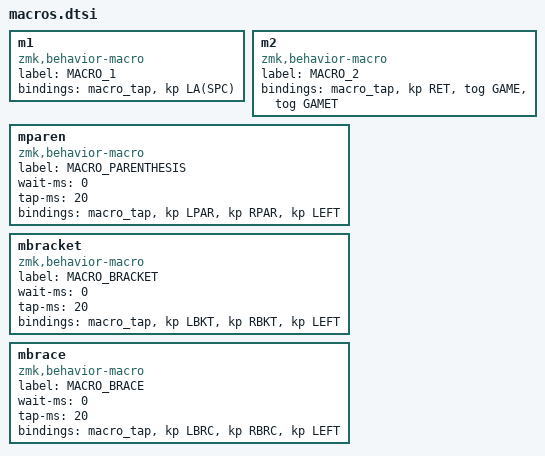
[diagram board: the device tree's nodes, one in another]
m1: m1 {
    compatible = "zmk,behavior-macro";
    label = "MACRO_1";
    #binding-cells = <0>;
    bindings = <&macro_tap &kp LA(SPC)>;
};

m2: m2 {
    compatible = "zmk,behavior-macro";
    label = "MACRO_2";
    #binding-cells = <0>;
    bindings = <&macro_tap &kp RET &tog GAME &tog GAMET>;
};

mparen: mparen {
    compatible = "zmk,behavior-macro";
    label = "MACRO_PARENTHESIS";
    #binding-cells = <0>;
    wait-ms = <0>;
    tap-ms = <20>;
    bindings = <&macro_tap &kp LPAR &kp RPAR &kp LEFT>;
};

mbracket: mbracket {
    compatible = "zmk,behavior-macro";
    label = "MACRO_BRACKET";
    #binding-cells = <0>;
    wait-ms = <0>;
    tap-ms = <20>;
    bindings = <&macro_tap &kp LBKT &kp RBKT &kp LEFT>;
};

mbrace: mbrace {
    compatible = "zmk,behavior-macro";
    label = "MACRO_BRACE";
    #binding-cells = <0>;
    wait-ms = <0>;
    tap-ms = <20>;
    bindings = <&macro_tap &kp LBRC &kp RBRC &kp LEFT>;
};
